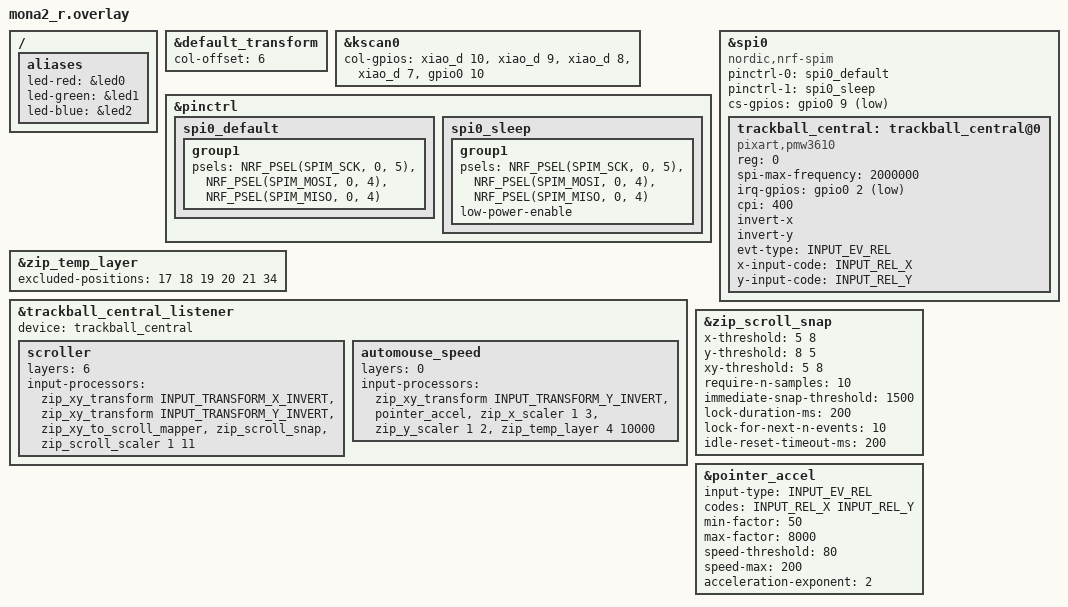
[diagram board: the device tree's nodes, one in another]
#include "mona2.dtsi"
#include <scroll-snap.dtsi>
#include <input/processors.dtsi>
#include <behaviors/input_gestures_accel.dtsi>
#include <zephyr/dt-bindings/input/input-event-codes.h>


&default_transform {
    col-offset = <6>;
};

&kscan0 {
        col-gpios
            = <&xiao_d 10 GPIO_ACTIVE_HIGH>
            , <&xiao_d 9 GPIO_ACTIVE_HIGH> 
            , <&xiao_d 8 GPIO_ACTIVE_HIGH> 
            , <&xiao_d 7 GPIO_ACTIVE_HIGH> 
            , <&gpio0 10 GPIO_ACTIVE_HIGH>
            ;
};


&pinctrl {
    spi0_default: spi0_default {    //通常時(SPI通信中)のピン構成
        group1 {
            psels = <NRF_PSEL(SPIM_SCK, 0, 5)>, //P0.05を指定(SCLK)
                <NRF_PSEL(SPIM_MOSI, 0, 4)>,    //P0.04を指定(SDIOだからMOSI,MISO両方の役割を担う)
                <NRF_PSEL(SPIM_MISO, 0, 4)>;
        };
    };

    spi0_sleep: spi0_sleep {    //スリープ時のピン構成(省電力)
        group1 {
            psels = <NRF_PSEL(SPIM_SCK, 0, 5)>,
                <NRF_PSEL(SPIM_MOSI, 0, 4)>,
                <NRF_PSEL(SPIM_MISO, 0, 4)>;
            low-power-enable;
        };
    };
};


&spi0 {
    status = "okay";
    compatible = "nordic,nrf-spim"; //マイコンがnRFシリーズ
    pinctrl-0 = <&spi0_default>;
    pinctrl-1 = <&spi0_sleep>;
    pinctrl-names = "default", "sleep";
    cs-gpios = <&gpio0 9 GPIO_ACTIVE_LOW>;  //P0.09を指定(CS)

    trackball_central: trackball_central@0 {
        status = "okay";
        compatible = "pixart,pmw3610";  //トラボセンサ用のドライバとバインド
        reg = <0>;
        spi-max-frequency = <2000000>;
        irq-gpios = <&gpio0 2 (GPIO_ACTIVE_LOW | GPIO_PULL_UP)>; //P0.02を指定(MOTION)
        cpi = <400>;
        //swap-xy;
        invert-x; //COROPIT版ではコメントアウトを外す
        invert-y; //COROPIT版ではコメントアウトを外す
        evt-type = <INPUT_EV_REL>;
        x-input-code = <INPUT_REL_X>;
        y-input-code = <INPUT_REL_Y>;
    };
};

// rgbled_adapter LED alias
/ {
    aliases {
        led-red   = &led0;
        led-green = &led1;
        led-blue  = &led2;
    };
};

&zip_temp_layer {
    excluded-positions = <
        17 // J
        18 // K
        19 // L
        20 // ;
        21 // LSHIFT,Z
        34 // Ctrl
    >;
};

// Overrides for the input listener node
&trackball_central_listener {
    status = "okay";
    device = <&trackball_central>;

    scroller {
        layers = <6>;
        input-processors = 
            // <&zip_xy_transform INPUT_TRANSFORM_XY_SWAP>,     //X軸とY軸の入れ替え
            <&zip_xy_transform INPUT_TRANSFORM_X_INVERT>,       //X軸反転
            <&zip_xy_transform INPUT_TRANSFORM_Y_INVERT>,       //Y軸反転
            <&zip_xy_to_scroll_mapper>,                         //スクロールモードに変更
            <&zip_scroll_snap>,                                 // scroll-snap を適用
            //<&zip_scroll_transform INPUT_TRANSFORM_X_INVERT>, //スクロールのX軸反転
            //<&pointer_accel>,                                 // アクセラレーションプロセッサ
            <&zip_scroll_scaler 1 11>;                          //スクロール量を1/11倍
    };

    // オートマウスレイヤー（4）専用の速度設定
    automouse_speed {
        layers = <0>;
        input-processors =
            <&zip_xy_transform INPUT_TRANSFORM_Y_INVERT>,
            <&pointer_accel>,                                   // アクセラレーションプロセッサ
            <&zip_x_scaler 1 3>,                                // 速度を 1/4 に
            <&zip_y_scaler 1 2>,                                // 速度を 1/2 に
            <&zip_temp_layer 4 10000>;                          // オートマウスレイヤー
    };
    
};

/* Optional: configure zip_scroll_snap parameters (override defaults). Adjust as needed. */
&zip_scroll_snap {
    x-threshold = <5 8>;
    y-threshold = <8 5>;
    xy-threshold = <5 8>;

    require-n-samples = <10>;
    immediate-snap-threshold = <1500>;

    lock-duration-ms = <200>;
    lock-for-next-n-events = <10>;
    idle-reset-timeout-ms = <200>;

};

&pointer_accel {
    input-type = <INPUT_EV_REL>;
    codes = <INPUT_REL_X INPUT_REL_Y>;
    // 低速をゆっくりに
    min-factor = <50>;         // 0.5倍(50)から0.25倍(25)へ：移動量が半分になります    
    max-factor = <8000>;  
    speed-threshold = <80>;   // 少しだけ低速維持範囲を広げる
    speed-max = <200>;    
    acceleration-exponent = <2>;
};
